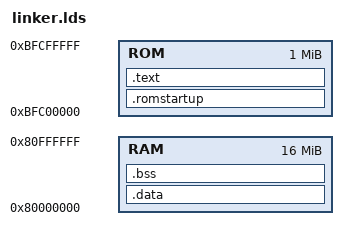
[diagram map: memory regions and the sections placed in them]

ENTRY(_start)

MEMORY
{
        /* RAM : ORIGIN = 0x00000000, LENGTH = 16M */
        /* RAM : ORIGIN = 0x18000000, LENGTH = 16M */
        RAM : ORIGIN = 0x80000000, LENGTH = 16M
        ROM : ORIGIN = 0xBFC00000, LENGTH = 1M
}

SECTIONS
{
        /**********************************************************************
         *                                                                    *
         **********************************************************************/
        .romstartup :
        {
                _sromstartup = .;
                /*KEEP(*(.vectors))*/
                *(.vectors)
                . = ALIGN(0x10);
                _eromstartup = .;
        } > ROM
        /**********************************************************************
         *                                                                    *
         **********************************************************************/
        .text :
        {
                _stext = .;
                *(.text)
                *(.text.*)
                *(.rodata)
                *(.rodata.*)
                /* *(.got1) */
                . = ALIGN(0x10);
                _etext = .;
        } > ROM
        /**********************************************************************
         *                                                                    *
         **********************************************************************/
        .data : AT(_etext)
        {
                _sdata = .;
                *(.data)
                *(.data.*)
                *(.sdata)
                *(.sdata.*)
                _sdata2 = .;
                *(.sdata2)
                *(.got.plt)
                *(.got)
                . = ALIGN(0x10);
                _edata = .;
        } > RAM
        /**********************************************************************
         *                                                                    *
         **********************************************************************/
        .bss ADDR(.data) + SIZEOF(.data) (NOLOAD) :
        {
                _sbss = .;
                *(.bss)
                *(.bss.*)
                *(COMMON)
                *(.sbss)
                *(.sbss.*)
                *(.scommon)
                *(.dynbss)
                . = ALIGN(0x10);
                _ebss = .;
        } > RAM
        /**********************************************************************
         *                                                                    *
         **********************************************************************/
        .debug_info    0 : { *(.debug_info) }
        .debug_abbrev  0 : { *(.debug_abbrev) }
        .debug_loc     0 : { *(.debug_loc) }
        .debug_aranges 0 : { *(.debug_aranges) }
        .debug_ranges  0 : { *(.debug_ranges) }
        .debug_line    0 : { *(.debug_line) }
        .debug_str     0 : { *(.debug_str) }
        /**********************************************************************
         *                                                                    *
         **********************************************************************/
        /DISCARD/ :
        {
                *(.comment)
                /* *(.eh_frame) */
                *(.MIPS.abiflags)
        }
}

